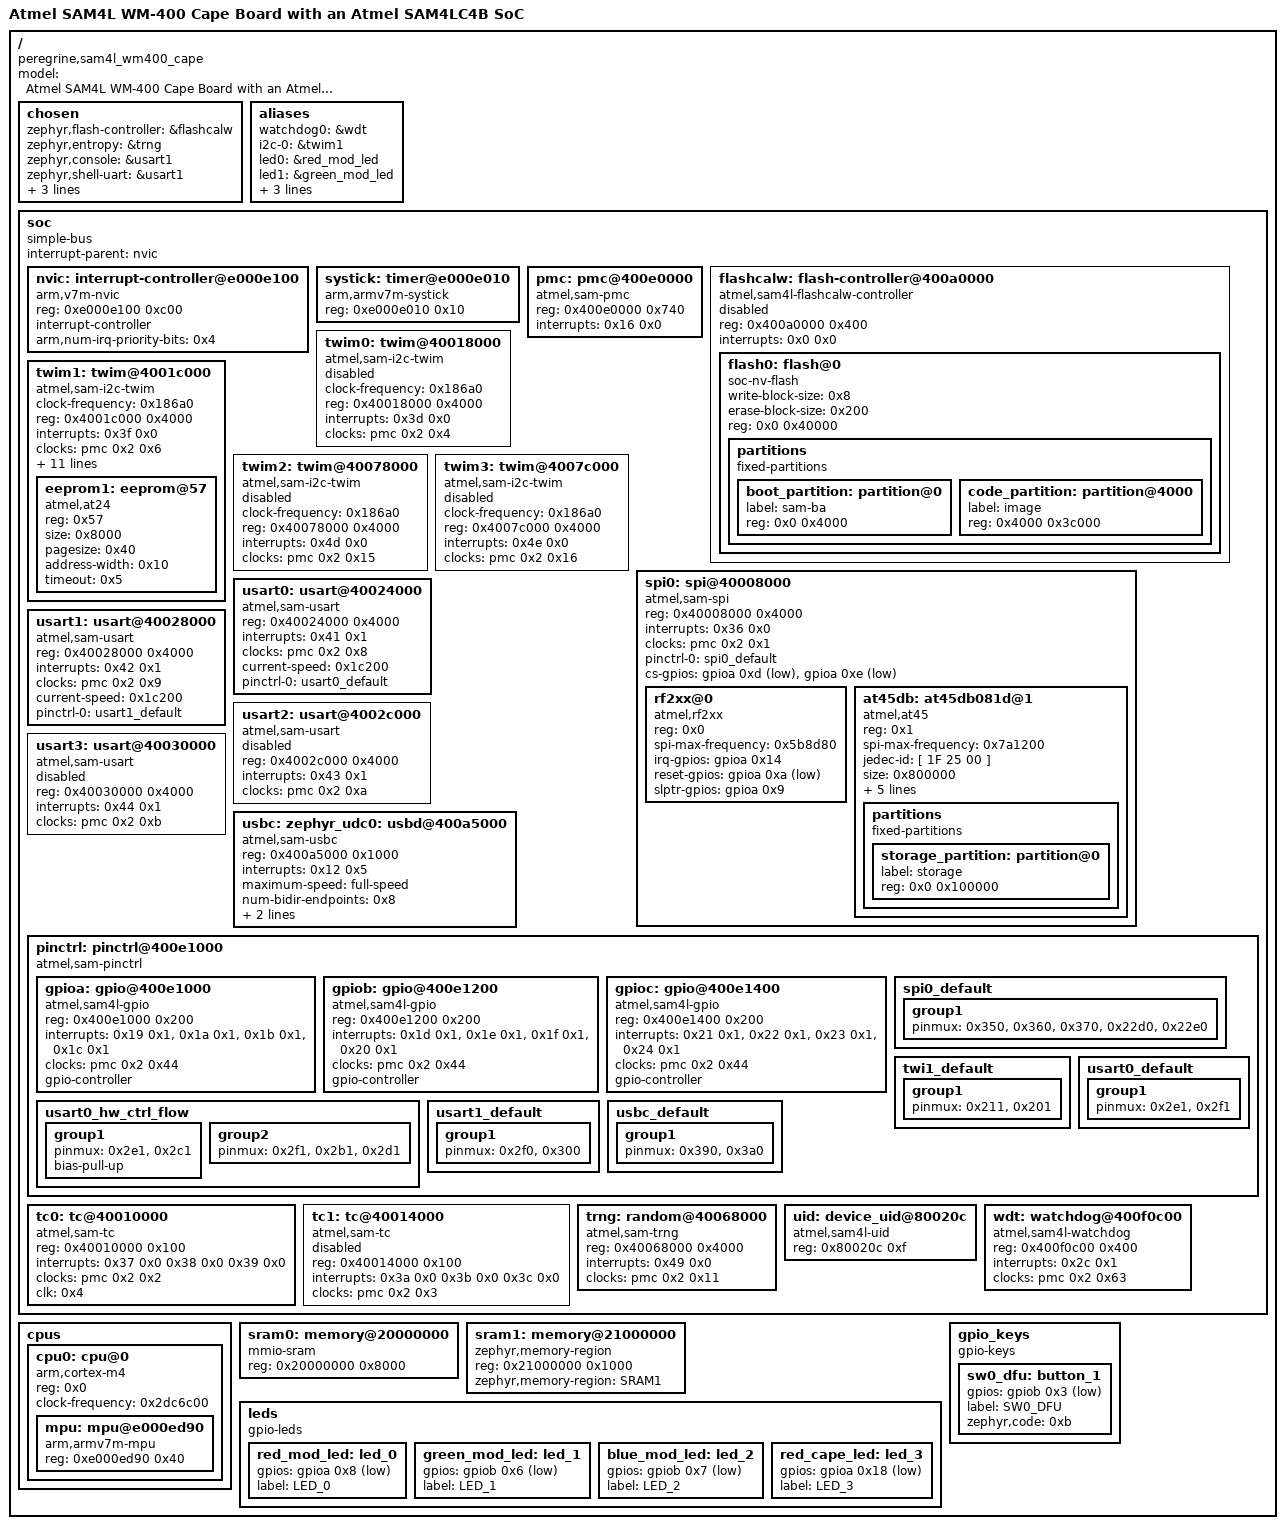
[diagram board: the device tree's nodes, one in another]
/dts-v1/;

/* node '/' defined in zephyr/dts/common/skeleton.dtsi:9 */
/ {
	#address-cells = < 0x1 >;                                           /* in zephyr/dts/common/skeleton.dtsi:10 */
	#size-cells = < 0x1 >;                                              /* in zephyr/dts/common/skeleton.dtsi:11 */
	model = "Atmel SAM4L WM-400 Cape Board with an Atmel SAM4LC4B SoC"; /* in zephyr/boards/peregrine/sam4l_wm400_cape/sam4l_wm400_cape.dts:13 */
	compatible = "peregrine,sam4l_wm400_cape",
	             "atmel,sam4lc4b",
	             "atmel,sam4l";                                         /* in zephyr/boards/peregrine/sam4l_wm400_cape/sam4l_wm400_cape.dts:14 */

	/* node '/chosen' defined in zephyr/dts/common/skeleton.dtsi:13 */
	chosen {
		zephyr,flash-controller = &flashcalw;    /* in zephyr/dts/arm/atmel/sam4l.dtsi:18 */
		zephyr,entropy = &trng;                  /* in zephyr/dts/arm/atmel/sam4l.dtsi:19 */
		zephyr,console = &usart1;                /* in zephyr/boards/peregrine/sam4l_wm400_cape/sam4l_wm400_cape.dts:26 */
		zephyr,shell-uart = &usart1;             /* in zephyr/boards/peregrine/sam4l_wm400_cape/sam4l_wm400_cape.dts:27 */
		zephyr,sram = &sram0;                    /* in zephyr/boards/peregrine/sam4l_wm400_cape/sam4l_wm400_cape.dts:28 */
		zephyr,flash = &flash0;                  /* in zephyr/boards/peregrine/sam4l_wm400_cape/sam4l_wm400_cape.dts:29 */
		zephyr,code-partition = &code_partition; /* in zephyr/boards/peregrine/sam4l_wm400_cape/sam4l_wm400_cape.dts:30 */
	};

	/* node '/aliases' defined in zephyr/dts/common/skeleton.dtsi:15 */
	aliases {
		watchdog0 = &wdt;      /* in zephyr/dts/arm/atmel/sam4l.dtsi:14 */
		i2c-0 = &twim1;        /* in zephyr/boards/peregrine/sam4l_wm400_cape/sam4l_wm400_cape.dts:17 */
		led0 = &red_mod_led;   /* in zephyr/boards/peregrine/sam4l_wm400_cape/sam4l_wm400_cape.dts:18 */
		led1 = &green_mod_led; /* in zephyr/boards/peregrine/sam4l_wm400_cape/sam4l_wm400_cape.dts:19 */
		led2 = &blue_mod_led;  /* in zephyr/boards/peregrine/sam4l_wm400_cape/sam4l_wm400_cape.dts:20 */
		led3 = &red_cape_led;  /* in zephyr/boards/peregrine/sam4l_wm400_cape/sam4l_wm400_cape.dts:21 */
		sw0 = &sw0_dfu;        /* in zephyr/boards/peregrine/sam4l_wm400_cape/sam4l_wm400_cape.dts:22 */
	};

	/* node '/soc' defined in zephyr/dts/arm/armv7-m.dtsi:6 */
	soc {
		#address-cells = < 0x1 >;     /* in zephyr/dts/arm/armv7-m.dtsi:7 */
		#size-cells = < 0x1 >;        /* in zephyr/dts/arm/armv7-m.dtsi:8 */
		compatible = "simple-bus";    /* in zephyr/dts/arm/armv7-m.dtsi:9 */
		interrupt-parent = < &nvic >; /* in zephyr/dts/arm/armv7-m.dtsi:10 */
		ranges;                       /* in zephyr/dts/arm/armv7-m.dtsi:11 */

		/* node '/soc/interrupt-controller@e000e100' defined in zephyr/dts/arm/armv7-m.dtsi:13 */
		nvic: interrupt-controller@e000e100 {
			#address-cells = < 0x1 >;            /* in zephyr/dts/arm/armv7-m.dtsi:14 */
			compatible = "arm,v7m-nvic";         /* in zephyr/dts/arm/armv7-m.dtsi:15 */
			reg = < 0xe000e100 0xc00 >;          /* in zephyr/dts/arm/armv7-m.dtsi:16 */
			interrupt-controller;                /* in zephyr/dts/arm/armv7-m.dtsi:17 */
			#interrupt-cells = < 0x2 >;          /* in zephyr/dts/arm/armv7-m.dtsi:18 */
			arm,num-irq-priority-bits = < 0x4 >; /* in zephyr/dts/arm/atmel/sam4l.dtsi:264 */
			phandle = < 0x1 >;                   /* in zephyr/dts/arm/armv7-m.dtsi:10 */
		};

		/* node '/soc/timer@e000e010' defined in zephyr/dts/arm/armv7-m.dtsi:21 */
		systick: timer@e000e010 {
			compatible = "arm,armv7m-systick"; /* in zephyr/dts/arm/armv7-m.dtsi:22 */
			reg = < 0xe000e010 0x10 >;         /* in zephyr/dts/arm/armv7-m.dtsi:23 */
		};

		/* node '/soc/pmc@400e0000' defined in zephyr/dts/arm/atmel/sam4l.dtsi:57 */
		pmc: pmc@400e0000 {
			compatible = "atmel,sam-pmc"; /* in zephyr/dts/arm/atmel/sam4l.dtsi:58 */
			reg = < 0x400e0000 0x740 >;   /* in zephyr/dts/arm/atmel/sam4l.dtsi:59 */
			interrupts = < 0x16 0x0 >;    /* in zephyr/dts/arm/atmel/sam4l.dtsi:60 */
			#clock-cells = < 0x2 >;       /* in zephyr/dts/arm/atmel/sam4l.dtsi:61 */
			status = "okay";              /* in zephyr/dts/arm/atmel/sam4l.dtsi:62 */
			phandle = < 0x2 >;            /* in zephyr/dts/arm/atmel/sam4l.dtsi:90 */
		};

		/* node '/soc/flash-controller@400a0000' defined in zephyr/dts/arm/atmel/sam4l.dtsi:65 */
		flashcalw: flash-controller@400a0000 {
			compatible = "atmel,sam4l-flashcalw-controller"; /* in zephyr/dts/arm/atmel/sam4l.dtsi:66 */
			reg = < 0x400a0000 0x400 >;                      /* in zephyr/dts/arm/atmel/sam4l.dtsi:67 */
			interrupts = < 0x0 0x0 >;                        /* in zephyr/dts/arm/atmel/sam4l.dtsi:68 */
			#address-cells = < 0x1 >;                        /* in zephyr/dts/arm/atmel/sam4l.dtsi:69 */
			#size-cells = < 0x1 >;                           /* in zephyr/dts/arm/atmel/sam4l.dtsi:70 */
			status = "disabled";                             /* in zephyr/dts/arm/atmel/sam4l.dtsi:82 */

			/* node '/soc/flash-controller@400a0000/flash@0' defined in zephyr/dts/arm/atmel/sam4l.dtsi:72 */
			flash0: flash@0 {
				compatible = "soc-nv-flash";  /* in zephyr/dts/arm/atmel/sam4l.dtsi:73 */
				write-block-size = < 0x8 >;   /* in zephyr/dts/arm/atmel/sam4l.dtsi:75 */
				erase-block-size = < 0x200 >; /* in zephyr/dts/arm/atmel/sam4l.dtsi:76 */
				reg = < 0x0 0x40000 >;        /* in zephyr/dts/arm/atmel/sam4lx4.dtsi:18 */

				/* node '/soc/flash-controller@400a0000/flash@0/partitions' defined in zephyr/boards/peregrine/sam4l_wm400_cape/sam4l_wm400_cape.dts:73 */
				partitions {
					compatible = "fixed-partitions"; /* in zephyr/boards/peregrine/sam4l_wm400_cape/sam4l_wm400_cape.dts:74 */
					#address-cells = < 0x1 >;        /* in zephyr/boards/peregrine/sam4l_wm400_cape/sam4l_wm400_cape.dts:75 */
					#size-cells = < 0x1 >;           /* in zephyr/boards/peregrine/sam4l_wm400_cape/sam4l_wm400_cape.dts:76 */

					/* node '/soc/flash-controller@400a0000/flash@0/partitions/partition@0' defined in zephyr/boards/peregrine/sam4l_wm400_cape/sam4l_wm400_cape.dts:78 */
					boot_partition: partition@0 {
						label = "sam-ba";     /* in zephyr/boards/peregrine/sam4l_wm400_cape/sam4l_wm400_cape.dts:79 */
						reg = < 0x0 0x4000 >; /* in zephyr/boards/peregrine/sam4l_wm400_cape/sam4l_wm400_cape.dts:80 */
					};

					/* node '/soc/flash-controller@400a0000/flash@0/partitions/partition@4000' defined in zephyr/boards/peregrine/sam4l_wm400_cape/sam4l_wm400_cape.dts:83 */
					code_partition: partition@4000 {
						label = "image";          /* in zephyr/boards/peregrine/sam4l_wm400_cape/sam4l_wm400_cape.dts:84 */
						reg = < 0x4000 0x3c000 >; /* in zephyr/boards/peregrine/sam4l_wm400_cape/sam4l_wm400_cape.dts:85 */
					};
				};
			};
		};

		/* node '/soc/twim@40018000' defined in zephyr/dts/arm/atmel/sam4l.dtsi:85 */
		twim0: twim@40018000 {
			compatible = "atmel,sam-i2c-twim"; /* in zephyr/dts/arm/atmel/sam4l.dtsi:86 */
			clock-frequency = < 0x186a0 >;     /* in zephyr/dts/arm/atmel/sam4l.dtsi:87 */
			reg = < 0x40018000 0x4000 >;       /* in zephyr/dts/arm/atmel/sam4l.dtsi:88 */
			interrupts = < 0x3d 0x0 >;         /* in zephyr/dts/arm/atmel/sam4l.dtsi:89 */
			clocks = < &pmc 0x2 0x4 >;         /* in zephyr/dts/arm/atmel/sam4l.dtsi:90 */
			status = "disabled";               /* in zephyr/dts/arm/atmel/sam4l.dtsi:91 */
			#address-cells = < 0x1 >;          /* in zephyr/dts/arm/atmel/sam4l.dtsi:92 */
			#size-cells = < 0x0 >;             /* in zephyr/dts/arm/atmel/sam4l.dtsi:93 */
		};

		/* node '/soc/twim@4001c000' defined in zephyr/dts/arm/atmel/sam4l.dtsi:96 */
		twim1: twim@4001c000 {
			compatible = "atmel,sam-i2c-twim"; /* in zephyr/dts/arm/atmel/sam4l.dtsi:97 */
			clock-frequency = < 0x186a0 >;     /* in zephyr/dts/arm/atmel/sam4l.dtsi:98 */
			reg = < 0x4001c000 0x4000 >;       /* in zephyr/dts/arm/atmel/sam4l.dtsi:99 */
			interrupts = < 0x3f 0x0 >;         /* in zephyr/dts/arm/atmel/sam4l.dtsi:100 */
			clocks = < &pmc 0x2 0x6 >;         /* in zephyr/dts/arm/atmel/sam4l.dtsi:101 */
			#address-cells = < 0x1 >;          /* in zephyr/dts/arm/atmel/sam4l.dtsi:103 */
			#size-cells = < 0x0 >;             /* in zephyr/dts/arm/atmel/sam4l.dtsi:104 */
			status = "okay";                   /* in zephyr/boards/peregrine/sam4l_wm400_cape/sam4l_wm400_cape.dts:140 */
			pinctrl-0 = < &twi1_default >;     /* in zephyr/boards/peregrine/sam4l_wm400_cape/sam4l_wm400_cape.dts:142 */
			pinctrl-names = "default";         /* in zephyr/boards/peregrine/sam4l_wm400_cape/sam4l_wm400_cape.dts:143 */
			std-clk-slew-lim = < 0x0 >;        /* in zephyr/boards/peregrine/sam4l_wm400_cape/sam4l_wm400_cape.dts:145 */
			std-clk-strength-low = "0.5";      /* in zephyr/boards/peregrine/sam4l_wm400_cape/sam4l_wm400_cape.dts:146 */
			std-data-slew-lim = < 0x0 >;       /* in zephyr/boards/peregrine/sam4l_wm400_cape/sam4l_wm400_cape.dts:147 */
			std-data-strength-low = "0.5";     /* in zephyr/boards/peregrine/sam4l_wm400_cape/sam4l_wm400_cape.dts:148 */
			hs-clk-slew-lim = < 0x0 >;         /* in zephyr/boards/peregrine/sam4l_wm400_cape/sam4l_wm400_cape.dts:150 */
			hs-clk-strength-high = "0.5";      /* in zephyr/boards/peregrine/sam4l_wm400_cape/sam4l_wm400_cape.dts:151 */
			hs-clk-strength-low = "0.5";       /* in zephyr/boards/peregrine/sam4l_wm400_cape/sam4l_wm400_cape.dts:152 */
			hs-data-slew-lim = < 0x0 >;        /* in zephyr/boards/peregrine/sam4l_wm400_cape/sam4l_wm400_cape.dts:153 */
			hs-data-strength-low = "0.5";      /* in zephyr/boards/peregrine/sam4l_wm400_cape/sam4l_wm400_cape.dts:154 */
			hs-master-code = < 0x0 >;          /* in zephyr/boards/peregrine/sam4l_wm400_cape/sam4l_wm400_cape.dts:156 */

			/* node '/soc/twim@4001c000/eeprom@57' defined in zephyr/boards/peregrine/sam4l_wm400_cape/sam4l_wm400_cape.dts:158 */
			eeprom1: eeprom@57 {
				compatible = "atmel,at24"; /* in zephyr/boards/peregrine/sam4l_wm400_cape/sam4l_wm400_cape.dts:159 */
				reg = < 0x57 >;            /* in zephyr/boards/peregrine/sam4l_wm400_cape/sam4l_wm400_cape.dts:160 */
				size = < 0x8000 >;         /* in zephyr/boards/peregrine/sam4l_wm400_cape/sam4l_wm400_cape.dts:161 */
				pagesize = < 0x40 >;       /* in zephyr/boards/peregrine/sam4l_wm400_cape/sam4l_wm400_cape.dts:162 */
				address-width = < 0x10 >;  /* in zephyr/boards/peregrine/sam4l_wm400_cape/sam4l_wm400_cape.dts:163 */
				timeout = < 0x5 >;         /* in zephyr/boards/peregrine/sam4l_wm400_cape/sam4l_wm400_cape.dts:164 */
			};
		};

		/* node '/soc/twim@40078000' defined in zephyr/dts/arm/atmel/sam4l.dtsi:107 */
		twim2: twim@40078000 {
			compatible = "atmel,sam-i2c-twim"; /* in zephyr/dts/arm/atmel/sam4l.dtsi:108 */
			clock-frequency = < 0x186a0 >;     /* in zephyr/dts/arm/atmel/sam4l.dtsi:109 */
			reg = < 0x40078000 0x4000 >;       /* in zephyr/dts/arm/atmel/sam4l.dtsi:110 */
			interrupts = < 0x4d 0x0 >;         /* in zephyr/dts/arm/atmel/sam4l.dtsi:111 */
			clocks = < &pmc 0x2 0x15 >;        /* in zephyr/dts/arm/atmel/sam4l.dtsi:112 */
			status = "disabled";               /* in zephyr/dts/arm/atmel/sam4l.dtsi:113 */
			#address-cells = < 0x1 >;          /* in zephyr/dts/arm/atmel/sam4l.dtsi:114 */
			#size-cells = < 0x0 >;             /* in zephyr/dts/arm/atmel/sam4l.dtsi:115 */
		};

		/* node '/soc/twim@4007c000' defined in zephyr/dts/arm/atmel/sam4l.dtsi:118 */
		twim3: twim@4007c000 {
			compatible = "atmel,sam-i2c-twim"; /* in zephyr/dts/arm/atmel/sam4l.dtsi:119 */
			clock-frequency = < 0x186a0 >;     /* in zephyr/dts/arm/atmel/sam4l.dtsi:120 */
			reg = < 0x4007c000 0x4000 >;       /* in zephyr/dts/arm/atmel/sam4l.dtsi:121 */
			interrupts = < 0x4e 0x0 >;         /* in zephyr/dts/arm/atmel/sam4l.dtsi:122 */
			clocks = < &pmc 0x2 0x16 >;        /* in zephyr/dts/arm/atmel/sam4l.dtsi:123 */
			status = "disabled";               /* in zephyr/dts/arm/atmel/sam4l.dtsi:124 */
			#address-cells = < 0x1 >;          /* in zephyr/dts/arm/atmel/sam4l.dtsi:125 */
			#size-cells = < 0x0 >;             /* in zephyr/dts/arm/atmel/sam4l.dtsi:126 */
		};

		/* node '/soc/spi@40008000' defined in zephyr/dts/arm/atmel/sam4l.dtsi:129 */
		spi0: spi@40008000 {
			compatible = "atmel,sam-spi";                   /* in zephyr/dts/arm/atmel/sam4l.dtsi:130 */
			reg = < 0x40008000 0x4000 >;                    /* in zephyr/dts/arm/atmel/sam4l.dtsi:131 */
			interrupts = < 0x36 0x0 >;                      /* in zephyr/dts/arm/atmel/sam4l.dtsi:132 */
			clocks = < &pmc 0x2 0x1 >;                      /* in zephyr/dts/arm/atmel/sam4l.dtsi:133 */
			#address-cells = < 0x1 >;                       /* in zephyr/dts/arm/atmel/sam4l.dtsi:135 */
			#size-cells = < 0x0 >;                          /* in zephyr/dts/arm/atmel/sam4l.dtsi:136 */
			status = "okay";                                /* in zephyr/boards/peregrine/sam4l_wm400_cape/sam4l_wm400_cape.dts:91 */
			pinctrl-0 = < &spi0_default >;                  /* in zephyr/boards/peregrine/sam4l_wm400_cape/sam4l_wm400_cape.dts:93 */
			pinctrl-names = "default";                      /* in zephyr/boards/peregrine/sam4l_wm400_cape/sam4l_wm400_cape.dts:94 */
			cs-gpios = < &gpioa 0xd 0x11 &gpioa 0xe 0x11 >; /* in zephyr/boards/peregrine/sam4l_wm400_cape/sam4l_wm400_cape.dts:96 */

			/* node '/soc/spi@40008000/rf2xx@0' defined in zephyr/boards/peregrine/sam4l_wm400_cape/sam4l_wm400_cape.dts:99 */
			rf2xx@0 {
				compatible = "atmel,rf2xx";       /* in zephyr/boards/peregrine/sam4l_wm400_cape/sam4l_wm400_cape.dts:100 */
				reg = < 0x0 >;                    /* in zephyr/boards/peregrine/sam4l_wm400_cape/sam4l_wm400_cape.dts:101 */
				spi-max-frequency = < 0x5b8d80 >; /* in zephyr/boards/peregrine/sam4l_wm400_cape/sam4l_wm400_cape.dts:102 */
				irq-gpios = < &gpioa 0x14 0x20 >; /* in zephyr/boards/peregrine/sam4l_wm400_cape/sam4l_wm400_cape.dts:103 */
				reset-gpios = < &gpioa 0xa 0x1 >; /* in zephyr/boards/peregrine/sam4l_wm400_cape/sam4l_wm400_cape.dts:104 */
				slptr-gpios = < &gpioa 0x9 0x0 >; /* in zephyr/boards/peregrine/sam4l_wm400_cape/sam4l_wm400_cape.dts:105 */
				status = "okay";                  /* in zephyr/boards/peregrine/sam4l_wm400_cape/sam4l_wm400_cape.dts:106 */
			};

			/* node '/soc/spi@40008000/at45db081d@1' defined in zephyr/boards/peregrine/sam4l_wm400_cape/sam4l_wm400_cape.dts:109 */
			at45db: at45db081d@1 {
				compatible = "atmel,at45";        /* in zephyr/boards/peregrine/sam4l_wm400_cape/sam4l_wm400_cape.dts:110 */
				reg = < 0x1 >;                    /* in zephyr/boards/peregrine/sam4l_wm400_cape/sam4l_wm400_cape.dts:111 */
				spi-max-frequency = < 0x7a1200 >; /* in zephyr/boards/peregrine/sam4l_wm400_cape/sam4l_wm400_cape.dts:112 */
				jedec-id = [ 1F 25 00 ];          /* in zephyr/boards/peregrine/sam4l_wm400_cape/sam4l_wm400_cape.dts:113 */
				size = < 0x800000 >;              /* in zephyr/boards/peregrine/sam4l_wm400_cape/sam4l_wm400_cape.dts:114 */
				sector-size = < 0x10000 >;        /* in zephyr/boards/peregrine/sam4l_wm400_cape/sam4l_wm400_cape.dts:115 */
				block-size = < 0x800 >;           /* in zephyr/boards/peregrine/sam4l_wm400_cape/sam4l_wm400_cape.dts:116 */
				page-size = < 0x100 >;            /* in zephyr/boards/peregrine/sam4l_wm400_cape/sam4l_wm400_cape.dts:117 */
				enter-dpd-delay = < 0xbb8 >;      /* in zephyr/boards/peregrine/sam4l_wm400_cape/sam4l_wm400_cape.dts:118 */
				exit-dpd-delay = < 0x88b8 >;      /* in zephyr/boards/peregrine/sam4l_wm400_cape/sam4l_wm400_cape.dts:119 */

				/* node '/soc/spi@40008000/at45db081d@1/partitions' defined in zephyr/boards/peregrine/sam4l_wm400_cape/sam4l_wm400_cape.dts:121 */
				partitions {
					compatible = "fixed-partitions"; /* in zephyr/boards/peregrine/sam4l_wm400_cape/sam4l_wm400_cape.dts:122 */
					#address-cells = < 0x1 >;        /* in zephyr/boards/peregrine/sam4l_wm400_cape/sam4l_wm400_cape.dts:123 */
					#size-cells = < 0x1 >;           /* in zephyr/boards/peregrine/sam4l_wm400_cape/sam4l_wm400_cape.dts:124 */

					/* node '/soc/spi@40008000/at45db081d@1/partitions/partition@0' defined in zephyr/boards/peregrine/sam4l_wm400_cape/sam4l_wm400_cape.dts:126 */
					storage_partition: partition@0 {
						label = "storage";      /* in zephyr/boards/peregrine/sam4l_wm400_cape/sam4l_wm400_cape.dts:127 */
						reg = < 0x0 0x100000 >; /* in zephyr/boards/peregrine/sam4l_wm400_cape/sam4l_wm400_cape.dts:128 */
					};
				};
			};
		};

		/* node '/soc/usart@40024000' defined in zephyr/dts/arm/atmel/sam4l.dtsi:139 */
		usart0: usart@40024000 {
			compatible = "atmel,sam-usart";  /* in zephyr/dts/arm/atmel/sam4l.dtsi:140 */
			reg = < 0x40024000 0x4000 >;     /* in zephyr/dts/arm/atmel/sam4l.dtsi:141 */
			interrupts = < 0x41 0x1 >;       /* in zephyr/dts/arm/atmel/sam4l.dtsi:142 */
			clocks = < &pmc 0x2 0x8 >;       /* in zephyr/dts/arm/atmel/sam4l.dtsi:143 */
			status = "okay";                 /* in zephyr/boards/peregrine/sam4l_wm400_cape/sam4l_wm400_cape.dts:169 */
			current-speed = < 0x1c200 >;     /* in zephyr/boards/peregrine/sam4l_wm400_cape/sam4l_wm400_cape.dts:170 */
			pinctrl-0 = < &usart0_default >; /* in zephyr/boards/peregrine/sam4l_wm400_cape/sam4l_wm400_cape.dts:172 */
			pinctrl-names = "default";       /* in zephyr/boards/peregrine/sam4l_wm400_cape/sam4l_wm400_cape.dts:173 */
		};

		/* node '/soc/usart@40028000' defined in zephyr/dts/arm/atmel/sam4l.dtsi:147 */
		usart1: usart@40028000 {
			compatible = "atmel,sam-usart";  /* in zephyr/dts/arm/atmel/sam4l.dtsi:148 */
			reg = < 0x40028000 0x4000 >;     /* in zephyr/dts/arm/atmel/sam4l.dtsi:149 */
			interrupts = < 0x42 0x1 >;       /* in zephyr/dts/arm/atmel/sam4l.dtsi:150 */
			clocks = < &pmc 0x2 0x9 >;       /* in zephyr/dts/arm/atmel/sam4l.dtsi:151 */
			status = "okay";                 /* in zephyr/boards/peregrine/sam4l_wm400_cape/sam4l_wm400_cape.dts:177 */
			current-speed = < 0x1c200 >;     /* in zephyr/boards/peregrine/sam4l_wm400_cape/sam4l_wm400_cape.dts:178 */
			pinctrl-0 = < &usart1_default >; /* in zephyr/boards/peregrine/sam4l_wm400_cape/sam4l_wm400_cape.dts:180 */
			pinctrl-names = "default";       /* in zephyr/boards/peregrine/sam4l_wm400_cape/sam4l_wm400_cape.dts:181 */
		};

		/* node '/soc/usart@4002c000' defined in zephyr/dts/arm/atmel/sam4l.dtsi:155 */
		usart2: usart@4002c000 {
			compatible = "atmel,sam-usart"; /* in zephyr/dts/arm/atmel/sam4l.dtsi:156 */
			reg = < 0x4002c000 0x4000 >;    /* in zephyr/dts/arm/atmel/sam4l.dtsi:157 */
			interrupts = < 0x43 0x1 >;      /* in zephyr/dts/arm/atmel/sam4l.dtsi:158 */
			clocks = < &pmc 0x2 0xa >;      /* in zephyr/dts/arm/atmel/sam4l.dtsi:159 */
			status = "disabled";            /* in zephyr/dts/arm/atmel/sam4l.dtsi:160 */
		};

		/* node '/soc/usart@40030000' defined in zephyr/dts/arm/atmel/sam4l.dtsi:163 */
		usart3: usart@40030000 {
			compatible = "atmel,sam-usart"; /* in zephyr/dts/arm/atmel/sam4l.dtsi:164 */
			reg = < 0x40030000 0x4000 >;    /* in zephyr/dts/arm/atmel/sam4l.dtsi:165 */
			interrupts = < 0x44 0x1 >;      /* in zephyr/dts/arm/atmel/sam4l.dtsi:166 */
			clocks = < &pmc 0x2 0xb >;      /* in zephyr/dts/arm/atmel/sam4l.dtsi:167 */
			status = "disabled";            /* in zephyr/dts/arm/atmel/sam4l.dtsi:168 */
		};

		/* node '/soc/usbd@400a5000' defined in zephyr/dts/arm/atmel/sam4l.dtsi:171 */
		usbc: zephyr_udc0: usbd@400a5000 {
			compatible = "atmel,sam-usbc"; /* in zephyr/dts/arm/atmel/sam4l.dtsi:172 */
			reg = < 0x400a5000 0x1000 >;   /* in zephyr/dts/arm/atmel/sam4l.dtsi:173 */
			interrupts = < 0x12 0x5 >;     /* in zephyr/dts/arm/atmel/sam4l.dtsi:174 */
			interrupt-names = "usbc";      /* in zephyr/dts/arm/atmel/sam4l.dtsi:175 */
			maximum-speed = "full-speed";  /* in zephyr/dts/arm/atmel/sam4l.dtsi:176 */
			num-bidir-endpoints = < 0x8 >; /* in zephyr/dts/arm/atmel/sam4l.dtsi:177 */
			clocks = < &pmc 0x2 0x65 >;    /* in zephyr/dts/arm/atmel/sam4l.dtsi:178 */
			status = "okay";               /* in zephyr/boards/peregrine/sam4l_wm400_cape/sam4l_wm400_cape.dts:185 */
			pinctrl-0 = < &usbc_default >; /* in zephyr/boards/peregrine/sam4l_wm400_cape/sam4l_wm400_cape.dts:187 */
			pinctrl-names = "default";     /* in zephyr/boards/peregrine/sam4l_wm400_cape/sam4l_wm400_cape.dts:188 */
		};

		/* node '/soc/pinctrl@400e1000' defined in zephyr/dts/arm/atmel/sam4l.dtsi:182 */
		pinctrl: pinctrl@400e1000 {
			compatible = "atmel,sam-pinctrl";         /* in zephyr/dts/arm/atmel/sam4l.dtsi:183 */
			#address-cells = < 0x1 >;                 /* in zephyr/dts/arm/atmel/sam4l.dtsi:184 */
			#size-cells = < 0x1 >;                    /* in zephyr/dts/arm/atmel/sam4l.dtsi:185 */
			ranges = < 0x400e1000 0x400e1000 0x800 >; /* in zephyr/dts/arm/atmel/sam4l.dtsi:186 */

			/* node '/soc/pinctrl@400e1000/gpio@400e1000' defined in zephyr/dts/arm/atmel/sam4l.dtsi:188 */
			gpioa: gpio@400e1000 {
				compatible = "atmel,sam4l-gpio"; /* in zephyr/dts/arm/atmel/sam4l.dtsi:189 */
				reg = < 0x400e1000 0x200 >;      /* in zephyr/dts/arm/atmel/sam4l.dtsi:190 */
				interrupts = < 0x19 0x1 >,
				             < 0x1a 0x1 >,
				             < 0x1b 0x1 >,
				             < 0x1c 0x1 >;       /* in zephyr/dts/arm/atmel/sam4l.dtsi:191 */
				clocks = < &pmc 0x2 0x44 >;      /* in zephyr/dts/arm/atmel/sam4l.dtsi:192 */
				gpio-controller;                 /* in zephyr/dts/arm/atmel/sam4l.dtsi:193 */
				#gpio-cells = < 0x2 >;           /* in zephyr/dts/arm/atmel/sam4l.dtsi:194 */
				#atmel,pin-cells = < 0x2 >;      /* in zephyr/dts/arm/atmel/sam4l.dtsi:195 */
				phandle = < 0x5 >;               /* in zephyr/boards/peregrine/sam4l_wm400_cape/sam4l_wm400_cape.dts:96 */
			};

			/* node '/soc/pinctrl@400e1000/gpio@400e1200' defined in zephyr/dts/arm/atmel/sam4l.dtsi:198 */
			gpiob: gpio@400e1200 {
				compatible = "atmel,sam4l-gpio"; /* in zephyr/dts/arm/atmel/sam4l.dtsi:199 */
				reg = < 0x400e1200 0x200 >;      /* in zephyr/dts/arm/atmel/sam4l.dtsi:200 */
				interrupts = < 0x1d 0x1 >,
				             < 0x1e 0x1 >,
				             < 0x1f 0x1 >,
				             < 0x20 0x1 >;       /* in zephyr/dts/arm/atmel/sam4l.dtsi:201 */
				clocks = < &pmc 0x2 0x44 >;      /* in zephyr/dts/arm/atmel/sam4l.dtsi:202 */
				gpio-controller;                 /* in zephyr/dts/arm/atmel/sam4l.dtsi:203 */
				#gpio-cells = < 0x2 >;           /* in zephyr/dts/arm/atmel/sam4l.dtsi:204 */
				#atmel,pin-cells = < 0x2 >;      /* in zephyr/dts/arm/atmel/sam4l.dtsi:205 */
				phandle = < 0x9 >;               /* in zephyr/boards/peregrine/sam4l_wm400_cape/sam4l_wm400_cape.dts:42 */
			};

			/* node '/soc/pinctrl@400e1000/gpio@400e1400' defined in zephyr/dts/arm/atmel/sam4l.dtsi:208 */
			gpioc: gpio@400e1400 {
				compatible = "atmel,sam4l-gpio"; /* in zephyr/dts/arm/atmel/sam4l.dtsi:209 */
				reg = < 0x400e1400 0x200 >;      /* in zephyr/dts/arm/atmel/sam4l.dtsi:210 */
				interrupts = < 0x21 0x1 >,
				             < 0x22 0x1 >,
				             < 0x23 0x1 >,
				             < 0x24 0x1 >;       /* in zephyr/dts/arm/atmel/sam4l.dtsi:211 */
				clocks = < &pmc 0x2 0x44 >;      /* in zephyr/dts/arm/atmel/sam4l.dtsi:212 */
				gpio-controller;                 /* in zephyr/dts/arm/atmel/sam4l.dtsi:213 */
				#gpio-cells = < 0x2 >;           /* in zephyr/dts/arm/atmel/sam4l.dtsi:214 */
				#atmel,pin-cells = < 0x2 >;      /* in zephyr/dts/arm/atmel/sam4l.dtsi:215 */
			};

			/* node '/soc/pinctrl@400e1000/spi0_default' defined in zephyr/boards/peregrine/sam4l_wm400_cape/sam4l_wm400_cape-pinctrl.dtsi:9 */
			spi0_default: spi0_default {
				phandle = < 0x4 >; /* in zephyr/boards/peregrine/sam4l_wm400_cape/sam4l_wm400_cape.dts:93 */

				/* node '/soc/pinctrl@400e1000/spi0_default/group1' defined in zephyr/boards/peregrine/sam4l_wm400_cape/sam4l_wm400_cape-pinctrl.dtsi:10 */
				group1 {
					pinmux = < 0x350 >,
					         < 0x360 >,
					         < 0x370 >,
					         < 0x22d0 >,
					         < 0x22e0 >; /* in zephyr/boards/peregrine/sam4l_wm400_cape/sam4l_wm400_cape-pinctrl.dtsi:11 */
				};
			};

			/* node '/soc/pinctrl@400e1000/twi1_default' defined in zephyr/boards/peregrine/sam4l_wm400_cape/sam4l_wm400_cape-pinctrl.dtsi:19 */
			twi1_default: twi1_default {
				phandle = < 0x3 >; /* in zephyr/boards/peregrine/sam4l_wm400_cape/sam4l_wm400_cape.dts:142 */

				/* node '/soc/pinctrl@400e1000/twi1_default/group1' defined in zephyr/boards/peregrine/sam4l_wm400_cape/sam4l_wm400_cape-pinctrl.dtsi:20 */
				group1 {
					pinmux = < 0x211 >,
					         < 0x201 >; /* in zephyr/boards/peregrine/sam4l_wm400_cape/sam4l_wm400_cape-pinctrl.dtsi:21 */
				};
			};

			/* node '/soc/pinctrl@400e1000/usart0_default' defined in zephyr/boards/peregrine/sam4l_wm400_cape/sam4l_wm400_cape-pinctrl.dtsi:26 */
			usart0_default: usart0_default {
				phandle = < 0x6 >; /* in zephyr/boards/peregrine/sam4l_wm400_cape/sam4l_wm400_cape.dts:172 */

				/* node '/soc/pinctrl@400e1000/usart0_default/group1' defined in zephyr/boards/peregrine/sam4l_wm400_cape/sam4l_wm400_cape-pinctrl.dtsi:27 */
				group1 {
					pinmux = < 0x2e1 >,
					         < 0x2f1 >; /* in zephyr/boards/peregrine/sam4l_wm400_cape/sam4l_wm400_cape-pinctrl.dtsi:28 */
				};
			};

			/* node '/soc/pinctrl@400e1000/usart0_hw_ctrl_flow' defined in zephyr/boards/peregrine/sam4l_wm400_cape/sam4l_wm400_cape-pinctrl.dtsi:33 */
			usart0_hw_ctrl_flow: usart0_hw_ctrl_flow {

				/* node '/soc/pinctrl@400e1000/usart0_hw_ctrl_flow/group1' defined in zephyr/boards/peregrine/sam4l_wm400_cape/sam4l_wm400_cape-pinctrl.dtsi:34 */
				group1 {
					pinmux = < 0x2e1 >,
					         < 0x2c1 >; /* in zephyr/boards/peregrine/sam4l_wm400_cape/sam4l_wm400_cape-pinctrl.dtsi:35 */
					bias-pull-up;       /* in zephyr/boards/peregrine/sam4l_wm400_cape/sam4l_wm400_cape-pinctrl.dtsi:37 */
				};

				/* node '/soc/pinctrl@400e1000/usart0_hw_ctrl_flow/group2' defined in zephyr/boards/peregrine/sam4l_wm400_cape/sam4l_wm400_cape-pinctrl.dtsi:40 */
				group2 {
					pinmux = < 0x2f1 >,
					         < 0x2b1 >,
					         < 0x2d1 >; /* in zephyr/boards/peregrine/sam4l_wm400_cape/sam4l_wm400_cape-pinctrl.dtsi:41 */
				};
			};

			/* node '/soc/pinctrl@400e1000/usart1_default' defined in zephyr/boards/peregrine/sam4l_wm400_cape/sam4l_wm400_cape-pinctrl.dtsi:47 */
			usart1_default: usart1_default {
				phandle = < 0x7 >; /* in zephyr/boards/peregrine/sam4l_wm400_cape/sam4l_wm400_cape.dts:180 */

				/* node '/soc/pinctrl@400e1000/usart1_default/group1' defined in zephyr/boards/peregrine/sam4l_wm400_cape/sam4l_wm400_cape-pinctrl.dtsi:48 */
				group1 {
					pinmux = < 0x2f0 >,
					         < 0x300 >; /* in zephyr/boards/peregrine/sam4l_wm400_cape/sam4l_wm400_cape-pinctrl.dtsi:49 */
				};
			};

			/* node '/soc/pinctrl@400e1000/usbc_default' defined in zephyr/boards/peregrine/sam4l_wm400_cape/sam4l_wm400_cape-pinctrl.dtsi:54 */
			usbc_default: usbc_default {
				phandle = < 0x8 >; /* in zephyr/boards/peregrine/sam4l_wm400_cape/sam4l_wm400_cape.dts:187 */

				/* node '/soc/pinctrl@400e1000/usbc_default/group1' defined in zephyr/boards/peregrine/sam4l_wm400_cape/sam4l_wm400_cape-pinctrl.dtsi:55 */
				group1 {
					pinmux = < 0x390 >,
					         < 0x3a0 >; /* in zephyr/boards/peregrine/sam4l_wm400_cape/sam4l_wm400_cape-pinctrl.dtsi:56 */
				};
			};
		};

		/* node '/soc/tc@40010000' defined in zephyr/dts/arm/atmel/sam4l.dtsi:219 */
		tc0: tc@40010000 {
			compatible = "atmel,sam-tc";                 /* in zephyr/dts/arm/atmel/sam4l.dtsi:220 */
			reg = < 0x40010000 0x100 >;                  /* in zephyr/dts/arm/atmel/sam4l.dtsi:221 */
			interrupts = < 0x37 0x0 0x38 0x0 0x39 0x0 >; /* in zephyr/dts/arm/atmel/sam4l.dtsi:222 */
			clocks = < &pmc 0x2 0x2 >;                   /* in zephyr/dts/arm/atmel/sam4l.dtsi:225 */
			clk = < 0x4 >;                               /* in zephyr/boards/peregrine/sam4l_wm400_cape/sam4l_wm400_cape.dts:135 */
			status = "okay";                             /* in zephyr/boards/peregrine/sam4l_wm400_cape/sam4l_wm400_cape.dts:136 */
		};

		/* node '/soc/tc@40014000' defined in zephyr/dts/arm/atmel/sam4l.dtsi:229 */
		tc1: tc@40014000 {
			compatible = "atmel,sam-tc";                 /* in zephyr/dts/arm/atmel/sam4l.dtsi:230 */
			reg = < 0x40014000 0x100 >;                  /* in zephyr/dts/arm/atmel/sam4l.dtsi:231 */
			interrupts = < 0x3a 0x0 0x3b 0x0 0x3c 0x0 >; /* in zephyr/dts/arm/atmel/sam4l.dtsi:232 */
			clocks = < &pmc 0x2 0x3 >;                   /* in zephyr/dts/arm/atmel/sam4l.dtsi:235 */
			status = "disabled";                         /* in zephyr/dts/arm/atmel/sam4l.dtsi:236 */
		};

		/* node '/soc/random@40068000' defined in zephyr/dts/arm/atmel/sam4l.dtsi:239 */
		trng: random@40068000 {
			compatible = "atmel,sam-trng"; /* in zephyr/dts/arm/atmel/sam4l.dtsi:240 */
			reg = < 0x40068000 0x4000 >;   /* in zephyr/dts/arm/atmel/sam4l.dtsi:241 */
			interrupts = < 0x49 0x0 >;     /* in zephyr/dts/arm/atmel/sam4l.dtsi:242 */
			clocks = < &pmc 0x2 0x11 >;    /* in zephyr/dts/arm/atmel/sam4l.dtsi:243 */
			status = "okay";               /* in zephyr/dts/arm/atmel/sam4l.dtsi:244 */
		};

		/* node '/soc/device_uid@80020c' defined in zephyr/dts/arm/atmel/sam4l.dtsi:247 */
		uid: device_uid@80020c {
			compatible = "atmel,sam4l-uid"; /* in zephyr/dts/arm/atmel/sam4l.dtsi:248 */
			reg = < 0x80020c 0xf >;         /* in zephyr/dts/arm/atmel/sam4l.dtsi:249 */
			status = "okay";                /* in zephyr/dts/arm/atmel/sam4l.dtsi:250 */
		};

		/* node '/soc/watchdog@400f0c00' defined in zephyr/dts/arm/atmel/sam4l.dtsi:253 */
		wdt: watchdog@400f0c00 {
			compatible = "atmel,sam4l-watchdog"; /* in zephyr/dts/arm/atmel/sam4l.dtsi:254 */
			reg = < 0x400f0c00 0x400 >;          /* in zephyr/dts/arm/atmel/sam4l.dtsi:255 */
			interrupts = < 0x2c 0x1 >;           /* in zephyr/dts/arm/atmel/sam4l.dtsi:256 */
			clocks = < &pmc 0x2 0x63 >;          /* in zephyr/dts/arm/atmel/sam4l.dtsi:257 */
			status = "okay";                     /* in zephyr/dts/arm/atmel/sam4l.dtsi:258 */
		};
	};

	/* node '/cpus' defined in zephyr/dts/arm/atmel/sam4l.dtsi:22 */
	cpus {
		#address-cells = < 0x1 >; /* in zephyr/dts/arm/atmel/sam4l.dtsi:23 */
		#size-cells = < 0x0 >;    /* in zephyr/dts/arm/atmel/sam4l.dtsi:24 */

		/* node '/cpus/cpu@0' defined in zephyr/dts/arm/atmel/sam4l.dtsi:26 */
		cpu0: cpu@0 {
			device_type = "cpu";             /* in zephyr/dts/arm/atmel/sam4l.dtsi:27 */
			compatible = "arm,cortex-m4";    /* in zephyr/dts/arm/atmel/sam4l.dtsi:28 */
			reg = < 0x0 >;                   /* in zephyr/dts/arm/atmel/sam4l.dtsi:29 */
			#address-cells = < 0x1 >;        /* in zephyr/dts/arm/atmel/sam4l.dtsi:30 */
			#size-cells = < 0x1 >;           /* in zephyr/dts/arm/atmel/sam4l.dtsi:31 */
			clock-frequency = < 0x2dc6c00 >; /* in zephyr/boards/peregrine/sam4l_wm400_cape/sam4l_wm400_cape.dts:69 */

			/* node '/cpus/cpu@0/mpu@e000ed90' defined in zephyr/dts/arm/atmel/sam4l.dtsi:33 */
			mpu: mpu@e000ed90 {
				compatible = "arm,armv7m-mpu"; /* in zephyr/dts/arm/atmel/sam4l.dtsi:34 */
				reg = < 0xe000ed90 0x40 >;     /* in zephyr/dts/arm/atmel/sam4l.dtsi:35 */
			};
		};
	};

	/* node '/memory@20000000' defined in zephyr/dts/arm/atmel/sam4l.dtsi:40 */
	sram0: memory@20000000 {
		compatible = "mmio-sram";    /* in zephyr/dts/arm/atmel/sam4l.dtsi:41 */
		reg = < 0x20000000 0x8000 >; /* in zephyr/dts/arm/atmel/sam4lx4.dtsi:12 */
	};

	/* node '/memory@21000000' defined in zephyr/dts/arm/atmel/sam4l.dtsi:50 */
	sram1: memory@21000000 {
		compatible = "zephyr,memory-region",
		             "mmio-sram";            /* in zephyr/dts/arm/atmel/sam4l.dtsi:51 */
		reg = < 0x21000000 0x1000 >;         /* in zephyr/dts/arm/atmel/sam4l.dtsi:52 */
		zephyr,memory-region = "SRAM1";      /* in zephyr/dts/arm/atmel/sam4l.dtsi:53 */
	};

	/* node '/leds' defined in zephyr/boards/peregrine/sam4l_wm400_cape/sam4l_wm400_cape.dts:33 */
	leds {
		compatible = "gpio-leds"; /* in zephyr/boards/peregrine/sam4l_wm400_cape/sam4l_wm400_cape.dts:34 */

		/* node '/leds/led_0' defined in zephyr/boards/peregrine/sam4l_wm400_cape/sam4l_wm400_cape.dts:36 */
		red_mod_led: led_0 {
			gpios = < &gpioa 0x8 0x1 >; /* in zephyr/boards/peregrine/sam4l_wm400_cape/sam4l_wm400_cape.dts:37 */
			label = "LED_0";            /* in zephyr/boards/peregrine/sam4l_wm400_cape/sam4l_wm400_cape.dts:38 */
		};

		/* node '/leds/led_1' defined in zephyr/boards/peregrine/sam4l_wm400_cape/sam4l_wm400_cape.dts:41 */
		green_mod_led: led_1 {
			gpios = < &gpiob 0x6 0x1 >; /* in zephyr/boards/peregrine/sam4l_wm400_cape/sam4l_wm400_cape.dts:42 */
			label = "LED_1";            /* in zephyr/boards/peregrine/sam4l_wm400_cape/sam4l_wm400_cape.dts:43 */
		};

		/* node '/leds/led_2' defined in zephyr/boards/peregrine/sam4l_wm400_cape/sam4l_wm400_cape.dts:46 */
		blue_mod_led: led_2 {
			gpios = < &gpiob 0x7 0x1 >; /* in zephyr/boards/peregrine/sam4l_wm400_cape/sam4l_wm400_cape.dts:47 */
			label = "LED_2";            /* in zephyr/boards/peregrine/sam4l_wm400_cape/sam4l_wm400_cape.dts:48 */
		};

		/* node '/leds/led_3' defined in zephyr/boards/peregrine/sam4l_wm400_cape/sam4l_wm400_cape.dts:51 */
		red_cape_led: led_3 {
			gpios = < &gpioa 0x18 0x1 >; /* in zephyr/boards/peregrine/sam4l_wm400_cape/sam4l_wm400_cape.dts:52 */
			label = "LED_3";             /* in zephyr/boards/peregrine/sam4l_wm400_cape/sam4l_wm400_cape.dts:53 */
		};
	};

	/* node '/gpio_keys' defined in zephyr/boards/peregrine/sam4l_wm400_cape/sam4l_wm400_cape.dts:57 */
	gpio_keys {
		compatible = "gpio-keys"; /* in zephyr/boards/peregrine/sam4l_wm400_cape/sam4l_wm400_cape.dts:58 */

		/* node '/gpio_keys/button_1' defined in zephyr/boards/peregrine/sam4l_wm400_cape/sam4l_wm400_cape.dts:60 */
		sw0_dfu: button_1 {
			gpios = < &gpiob 0x3 0x1 >; /* in zephyr/boards/peregrine/sam4l_wm400_cape/sam4l_wm400_cape.dts:61 */
			label = "SW0_DFU";          /* in zephyr/boards/peregrine/sam4l_wm400_cape/sam4l_wm400_cape.dts:62 */
			zephyr,code = < 0xb >;      /* in zephyr/boards/peregrine/sam4l_wm400_cape/sam4l_wm400_cape.dts:63 */
		};
	};
};
